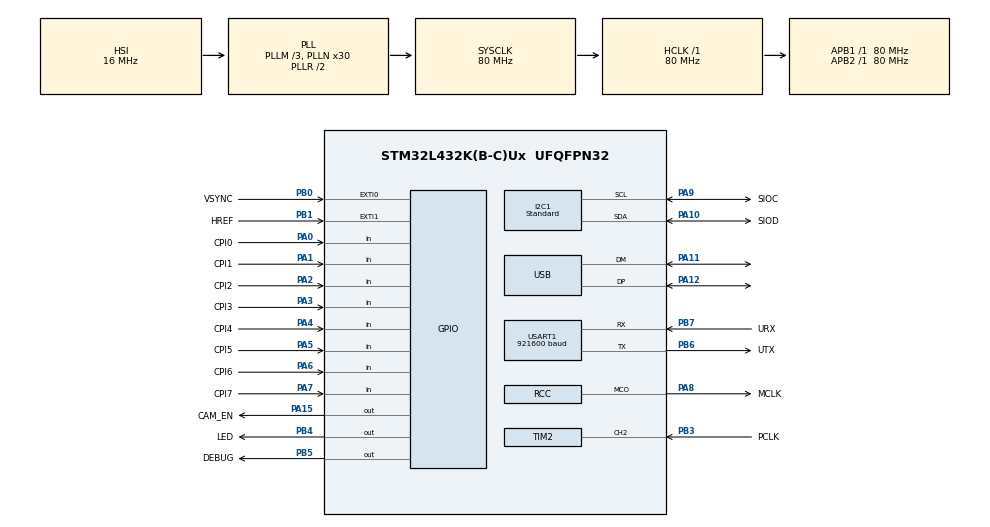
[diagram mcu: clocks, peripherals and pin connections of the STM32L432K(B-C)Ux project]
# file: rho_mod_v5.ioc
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Dma.Request0=TIM2_CH2/CH4
Dma.TIM2_CH2/CH4.0.Direction=DMA_PERIPH_TO_MEMORY
Dma.TIM2_CH2/CH4.0.Instance=DMA1_Channel7
Dma.TIM2_CH2/CH4.0.MemDataAlignment=DMA_MDATAALIGN_BYTE
Dma.TIM2_CH2/CH4.0.MemInc=DMA_MINC_ENABLE
Dma.TIM2_CH2/CH4.0.Mode=DMA_CIRCULAR
Dma.TIM2_CH2/CH4.0.PeriphDataAlignment=DMA_PDATAALIGN_BYTE
Dma.TIM2_CH2/CH4.0.PeriphInc=DMA_PINC_DISABLE
Dma.TIM2_CH2/CH4.0.Priority=DMA_PRIORITY_VERY_HIGH
I2C1.I2C_Speed_Mode=I2C_Standard
I2C1.OwnAddress=0x60
Mcu.Family=STM32L4
Mcu.Name=STM32L432K(B-C)Ux
Mcu.Package=UFQFPN32
NVIC.DMA1_Channel7_IRQn=true\:0\:0\:false\:true\:true\:4\:false\:true
NVIC.EXTI0_IRQn=true\:0\:2\:true\:true\:true\:1\:true\:true
NVIC.EXTI1_IRQn=true\:0\:1\:false\:true\:true\:2\:true\:true
NVIC.PriorityGroup=NVIC_PRIORITYGROUP_2
NVIC.USART1_IRQn=true\:0\:0\:false\:true\:true\:3\:true\:true
PA0.GPIO_Label=CPI0
PA0.Signal=GPIO_Input
PA1.GPIO_Label=CPI1
PA1.GPIO_Mode=GPIO_MODE_INPUT
PA1.GPIO_PuPd=GPIO_NOPULL
PA1.Signal=GPIO_Input
PA10.GPIO_Label=SIOD
PA10.Mode=I2C
PA10.Signal=I2C1_SDA
PA11.Mode=Device
PA11.Signal=USB_DM
PA12.Mode=Device
PA12.Signal=USB_DP
PA15\ (JTDI).GPIO_Label=CAM_EN
PA15\ (JTDI).GPIO_ModeDefaultOutputPP=GPIO_MODE_OUTPUT_PP
PA15\ (JTDI).GPIO_PuPd=GPIO_PULLUP
PA15\ (JTDI).GPIO_Speed=GPIO_SPEED_FREQ_LOW
PA15\ (JTDI).PinState=GPIO_PIN_RESET
PA15\ (JTDI).Signal=GPIO_Output
PA2.GPIO_Label=CPI2
PA2.GPIO_Mode=GPIO_MODE_INPUT
PA2.GPIO_PuPd=GPIO_NOPULL
PA2.Signal=GPIO_Input
PA3.GPIO_Label=CPI3
PA3.GPIO_Mode=GPIO_MODE_INPUT
PA3.GPIO_PuPd=GPIO_NOPULL
PA3.Signal=GPIO_Input
PA4.GPIO_Label=CPI4
PA4.GPIO_Mode=GPIO_MODE_INPUT
PA4.GPIO_PuPd=GPIO_NOPULL
PA4.Signal=GPIO_Input
PA5.GPIO_Label=CPI5
PA5.GPIO_Mode=GPIO_MODE_INPUT
PA5.GPIO_PuPd=GPIO_NOPULL
PA5.Signal=GPIO_Input
PA6.GPIO_Label=CPI6
PA6.GPIO_Mode=GPIO_MODE_INPUT
PA6.GPIO_PuPd=GPIO_NOPULL
PA6.Signal=GPIO_Input
PA7.GPIO_Label=CPI7
PA7.GPIO_Mode=GPIO_MODE_INPUT
PA7.GPIO_PuPd=GPIO_NOPULL
PA7.Signal=GPIO_Input
PA8.GPIO_Label=MCLK
PA8.Mode=Clock-out
PA8.Signal=RCC_MCO
PA9.GPIO_Label=SIOC
PA9.Mode=I2C
PA9.Signal=I2C1_SCL
PB0.GPIO_Label=VSYNC
PB0.GPIO_ModeDefaultEXTI=GPIO_MODE_IT_RISING_FALLING
PB0.GPIO_PuPd=GPIO_NOPULL
PB0.Signal=GPXTI0
PB1.GPIO_Label=HREF
PB1.GPIO_ModeDefaultEXTI=GPIO_MODE_IT_RISING_FALLING
PB1.Signal=GPXTI1
PB3\ (JTDO-TRACESWO).GPIO_Label=PCLK
PB3\ (JTDO-TRACESWO).GPIO_Speed=GPIO_SPEED_FREQ_VERY_HIGH
PB3\ (JTDO-TRACESWO).Signal=S_TIM2_CH2
PB4\ (NJTRST).GPIO_Label=LED
PB4\ (NJTRST).GPIO_PuPd=GPIO_PULLDOWN
PB4\ (NJTRST).Signal=GPIO_Output
PB5.GPIO_Label=DEBUG
PB5.Signal=GPIO_Output
PB6.GPIO_FM6=I2C_FASTMODEPLUS_PB6
PB6.GPIO_Label=UTX
PB6.Mode=Asynchronous
PB6.Signal=USART1_TX
PB7.GPIO_FM7=I2C_FASTMODEPLUS_PB7
PB7.GPIO_Label=URX
PB7.Mode=Asynchronous
PB7.Signal=USART1_RX
PC14-OSC32_IN\ (PC14).Mode=LSE-External-Oscillator
PC14-OSC32_IN\ (PC14).Signal=RCC_OSC32_IN
PC15-OSC32_OUT\ (PC15).Mode=LSE-External-Oscillator
PC15-OSC32_OUT\ (PC15).Signal=RCC_OSC32_OUT
ProjectManager.HeapSize=0x200
ProjectManager.StackSize=0x400
ProjectManager.TargetToolchain=EWARM V7
RCC.ADCFreq_Value=26666666.666666664
RCC.AHBFreq_Value=80000000
RCC.APB1Freq_Value=80000000
RCC.APB1TimFreq_Value=80000000
RCC.APB2Freq_Value=80000000
RCC.APB2TimFreq_Value=80000000
RCC.CK48CLockSelection=RCC_USBCLKSOURCE_HSI48
RCC.CortexFreq_Value=80000000
RCC.FLatency-AdvancedSettings=FLASH_LATENCY_4
RCC.HCLKFreq_Value=80000000
RCC.HSE_VALUE=48000000
RCC.HSI48_VALUE=48000000
RCC.HSI_VALUE=16000000
RCC.I2C1CLockSelection=RCC_I2C1CLKSOURCE_SYSCLK
RCC.MSIClockRange=RCC_MSIRANGE_11
RCC.MSI_VALUE=48000000
RCC.PLLM=3
RCC.PLLN=30
RCC.PLLSAI1N=10
RCC.PLLSourceVirtual=RCC_PLLSOURCE_HSI
RCC.RCC_MCO1Source=RCC_MCO1SOURCE_PLLCLK
RCC.RCC_MCODiv=RCC_MCODIV_4
RCC.SYSCLKFreq_VALUE=80000000
RCC.SYSCLKSource=RCC_SYSCLKSOURCE_PLLCLK
RCC.USBFreq_Value=48000000
RCC.VCOOutputFreq_Value=160000000
SH.S_TIM2_CH2.0=TIM2_CH2,Input_Capture2_from_TI2
SH.S_TIM2_CH2.1=TIM2_CH2,TriggerSource_TI2FP2
TIM2.AutoReloadPreload=TIM_AUTORELOAD_PRELOAD_ENABLE
TIM2.Channel-Input_Capture2_from_TI2=TIM_CHANNEL_2
TIM2.CounterMode=TIM_COUNTERMODE_UP
TIM2.ICFilter_CH2=0
TIM2.ICPolarity_CH2=TIM_INPUTCHANNELPOLARITY_FALLING
TIM2.Period=0
TIM2.TIM_MasterOutputTrigger=TIM_TRGO_OC1
USART1.BaudRate=921600
USART1.VirtualMode-Asynchronous=VM_ASYNC
VP_TIM2_VS_ControllerModeCombinedResetTrigger.Mode=Combined_Reset_Trigger_Mode
board=rho_mod_v4

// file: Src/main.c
/* USER CODE BEGIN Header */
/**
  ******************************************************************************
  * @file           : main.c
  * @brief          : Main program body
  ******************************************************************************
  * @attention
  *
  * <h2><center>&copy; Copyright (c) 2019 STMicroelectronics.
  * All rights reserved.</center></h2>
  *
  * This software component is licensed by ST under BSD 3-Clause license,
  * the "License"; You may not use this file except in compliance with the
  * License. You may obtain a copy of the License at:
  *                        opensource.org/licenses/BSD-3-Clause
  *
  ******************************************************************************
  */
/* USER CODE END Header */

#include "main.h"

/* USER CODE BEGIN Includes */
#include "master.h"
/* USER CODE END Includes */

I2C_HandleTypeDef hi2c1;

TIM_HandleTypeDef htim2;
DMA_HandleTypeDef hdma_tim2_ch2_ch4;

UART_HandleTypeDef huart1;

PCD_HandleTypeDef hpcd_USB_FS;

/* USER CODE BEGIN PV */
/* Private variables ---------------------------------------------------------*/

/* USER CODE END PV */

void SystemClock_Config(void);
static void MX_GPIO_Init(void);
static void MX_DMA_Init(void);
static void MX_I2C1_Init(void);
static void MX_USART1_UART_Init(void);
static void MX_TIM2_Init(void);
static void MX_USB_PCD_Init(void);
static void MX_NVIC_Init(void);
/* USER CODE BEGIN PFP */
/* Private function prototypes -----------------------------------------------*/

/* USER CODE END PFP */

int main(void)
{

  /* MCU Configuration--------------------------------------------------------*/

  /* Reset of all peripherals, Initializes the Flash interface and the Systick. */
  HAL_Init();

  /* Configure the system clock */
  SystemClock_Config();

  /* Initialize all configured peripherals */
  MX_GPIO_Init();
  MX_DMA_Init();
  MX_I2C1_Init();
  MX_USART1_UART_Init();
  MX_TIM2_Init();
  MX_USB_PCD_Init();

  /* Initialize interrupts */
  MX_NVIC_Init();
  /* USER CODE BEGIN 2 */
  MasterFunctions.Connect( &hi2c1, &htim2, &huart1 );
  /* USER CODE END 2 */

  /* Infinite loop */
  while (1)
  {

  }
}

void SystemClock_Config(void)
{
  RCC_OscInitTypeDef RCC_OscInitStruct = {0};
  RCC_ClkInitTypeDef RCC_ClkInitStruct = {0};
  RCC_PeriphCLKInitTypeDef PeriphClkInit = {0};

  /** Initializes the CPU, AHB and APB busses clocks
  */
  RCC_OscInitStruct.OscillatorType = RCC_OSCILLATORTYPE_HSI48|RCC_OSCILLATORTYPE_HSI;
  RCC_OscInitStruct.HSIState = RCC_HSI_ON;
  RCC_OscInitStruct.HSI48State = RCC_HSI48_ON;
  RCC_OscInitStruct.HSICalibrationValue = RCC_HSICALIBRATION_DEFAULT;
  RCC_OscInitStruct.PLL.PLLState = RCC_PLL_ON;
  RCC_OscInitStruct.PLL.PLLSource = RCC_PLLSOURCE_HSI;
  RCC_OscInitStruct.PLL.PLLM = 3;
  RCC_OscInitStruct.PLL.PLLN = 30;
  RCC_OscInitStruct.PLL.PLLP = RCC_PLLP_DIV7;
  RCC_OscInitStruct.PLL.PLLQ = RCC_PLLQ_DIV2;
  RCC_OscInitStruct.PLL.PLLR = RCC_PLLR_DIV2;
  if (HAL_RCC_OscConfig(&RCC_OscInitStruct) != HAL_OK)
  {
    Error_Handler();
  }
  /** Initializes the CPU, AHB and APB busses clocks
  */
  RCC_ClkInitStruct.ClockType = RCC_CLOCKTYPE_HCLK|RCC_CLOCKTYPE_SYSCLK
                              |RCC_CLOCKTYPE_PCLK1|RCC_CLOCKTYPE_PCLK2;
  RCC_ClkInitStruct.SYSCLKSource = RCC_SYSCLKSOURCE_PLLCLK;
  RCC_ClkInitStruct.AHBCLKDivider = RCC_SYSCLK_DIV1;
  RCC_ClkInitStruct.APB1CLKDivider = RCC_HCLK_DIV1;
  RCC_ClkInitStruct.APB2CLKDivider = RCC_HCLK_DIV1;

  if (HAL_RCC_ClockConfig(&RCC_ClkInitStruct, FLASH_LATENCY_4) != HAL_OK)
  {
    Error_Handler();
  }
  PeriphClkInit.PeriphClockSelection = RCC_PERIPHCLK_USART1|RCC_PERIPHCLK_I2C1
                              |RCC_PERIPHCLK_USB;
  PeriphClkInit.Usart1ClockSelection = RCC_USART1CLKSOURCE_PCLK2;
  PeriphClkInit.I2c1ClockSelection = RCC_I2C1CLKSOURCE_SYSCLK;
  PeriphClkInit.UsbClockSelection = RCC_USBCLKSOURCE_HSI48;
  if (HAL_RCCEx_PeriphCLKConfig(&PeriphClkInit) != HAL_OK)
  {
    Error_Handler();
  }
  HAL_RCC_MCOConfig(RCC_MCO1, RCC_MCO1SOURCE_PLLCLK, RCC_MCODIV_4);
  /** Configure the main internal regulator output voltage
  */
  if (HAL_PWREx_ControlVoltageScaling(PWR_REGULATOR_VOLTAGE_SCALE1) != HAL_OK)
  {
    Error_Handler();
  }
}

/**
  * @brief NVIC Configuration.
  * @retval None
  */
static void MX_NVIC_Init(void)
{
  /* EXTI0_IRQn interrupt configuration */
  HAL_NVIC_SetPriority(EXTI0_IRQn, 0, 2);
  HAL_NVIC_EnableIRQ(EXTI0_IRQn);
  /* EXTI1_IRQn interrupt configuration */
  HAL_NVIC_SetPriority(EXTI1_IRQn, 0, 1);
  HAL_NVIC_EnableIRQ(EXTI1_IRQn);
  /* USART1_IRQn interrupt configuration */
  HAL_NVIC_SetPriority(USART1_IRQn, 0, 0);
  HAL_NVIC_EnableIRQ(USART1_IRQn);
  /* DMA1_Channel7_IRQn interrupt configuration */
  HAL_NVIC_SetPriority(DMA1_Channel7_IRQn, 0, 0);
  HAL_NVIC_EnableIRQ(DMA1_Channel7_IRQn);
}

static void MX_I2C1_Init(void)
{

  hi2c1.Instance = I2C1;
  hi2c1.Init.Timing = 0x10909CEC;
  hi2c1.Init.OwnAddress1 = 192;
  hi2c1.Init.AddressingMode = I2C_ADDRESSINGMODE_7BIT;
  hi2c1.Init.DualAddressMode = I2C_DUALADDRESS_DISABLE;
  hi2c1.Init.OwnAddress2 = 0;
  hi2c1.Init.OwnAddress2Masks = I2C_OA2_NOMASK;
  hi2c1.Init.GeneralCallMode = I2C_GENERALCALL_DISABLE;
  hi2c1.Init.NoStretchMode = I2C_NOSTRETCH_DISABLE;
  if (HAL_I2C_Init(&hi2c1) != HAL_OK)
  {
    Error_Handler();
  }
  /** Configure Analogue filter
  */
  if (HAL_I2CEx_ConfigAnalogFilter(&hi2c1, I2C_ANALOGFILTER_ENABLE) != HAL_OK)
  {
    Error_Handler();
  }
  /** Configure Digital filter
  */
  if (HAL_I2CEx_ConfigDigitalFilter(&hi2c1, 0) != HAL_OK)
  {
    Error_Handler();
  }

}

static void MX_TIM2_Init(void)
{

  TIM_SlaveConfigTypeDef sSlaveConfig = {0};
  TIM_MasterConfigTypeDef sMasterConfig = {0};
  TIM_IC_InitTypeDef sConfigIC = {0};

  htim2.Instance = TIM2;
  htim2.Init.Prescaler = 0;
  htim2.Init.CounterMode = TIM_COUNTERMODE_UP;
  htim2.Init.Period = 0;
  htim2.Init.ClockDivision = TIM_CLOCKDIVISION_DIV1;
  htim2.Init.AutoReloadPreload = TIM_AUTORELOAD_PRELOAD_ENABLE;
  if (HAL_TIM_Base_Init(&htim2) != HAL_OK)
  {
    Error_Handler();
  }
  if (HAL_TIM_IC_Init(&htim2) != HAL_OK)
  {
    Error_Handler();
  }
  sSlaveConfig.SlaveMode = TIM_SLAVEMODE_COMBINED_RESETTRIGGER;
  sSlaveConfig.InputTrigger = TIM_TS_TI2FP2;
  sSlaveConfig.TriggerPolarity = TIM_INPUTCHANNELPOLARITY_FALLING;
  sSlaveConfig.TriggerFilter = 0;
  if (HAL_TIM_SlaveConfigSynchronization(&htim2, &sSlaveConfig) != HAL_OK)
  {
    Error_Handler();
  }
  sMasterConfig.MasterOutputTrigger = TIM_TRGO_OC1;
  sMasterConfig.MasterSlaveMode = TIM_MASTERSLAVEMODE_DISABLE;
  if (HAL_TIMEx_MasterConfigSynchronization(&htim2, &sMasterConfig) != HAL_OK)
  {
    Error_Handler();
  }
  sConfigIC.ICPolarity = TIM_INPUTCHANNELPOLARITY_FALLING;
  sConfigIC.ICSelection = TIM_ICSELECTION_DIRECTTI;
  sConfigIC.ICPrescaler = TIM_ICPSC_DIV1;
  sConfigIC.ICFilter = 0;
  if (HAL_TIM_IC_ConfigChannel(&htim2, &sConfigIC, TIM_CHANNEL_2) != HAL_OK)
  {
    Error_Handler();
  }

}

static void MX_USART1_UART_Init(void)
{

  huart1.Instance = USART1;
  huart1.Init.BaudRate = 921600;
  huart1.Init.WordLength = UART_WORDLENGTH_8B;
  huart1.Init.StopBits = UART_STOPBITS_1;
  huart1.Init.Parity = UART_PARITY_NONE;
  huart1.Init.Mode = UART_MODE_TX_RX;
  huart1.Init.HwFlowCtl = UART_HWCONTROL_NONE;
  huart1.Init.OverSampling = UART_OVERSAMPLING_16;
  huart1.Init.OneBitSampling = UART_ONE_BIT_SAMPLE_DISABLE;
  huart1.AdvancedInit.AdvFeatureInit = UART_ADVFEATURE_NO_INIT;
  if (HAL_UART_Init(&huart1) != HAL_OK)
  {
    Error_Handler();
  }

}

static void MX_USB_PCD_Init(void)
{

  hpcd_USB_FS.Instance = USB;
  hpcd_USB_FS.Init.dev_endpoints = 8;
  hpcd_USB_FS.Init.speed = PCD_SPEED_FULL;
  hpcd_USB_FS.Init.phy_itface = PCD_PHY_EMBEDDED;
  hpcd_USB_FS.Init.Sof_enable = DISABLE;
  hpcd_USB_FS.Init.low_power_enable = DISABLE;
  hpcd_USB_FS.Init.lpm_enable = DISABLE;
  hpcd_USB_FS.Init.battery_charging_enable = DISABLE;
  if (HAL_PCD_Init(&hpcd_USB_FS) != HAL_OK)
  {
    Error_Handler();
  }

}

static void MX_DMA_Init(void)
{
  /* DMA controller clock enable */
  __HAL_RCC_DMA1_CLK_ENABLE();

}

static void MX_GPIO_Init(void)
{
  GPIO_InitTypeDef GPIO_InitStruct = {0};

  /* GPIO Ports Clock Enable */
  __HAL_RCC_GPIOC_CLK_ENABLE();
  __HAL_RCC_GPIOA_CLK_ENABLE();
  __HAL_RCC_GPIOB_CLK_ENABLE();

  /*Configure GPIO pin Output Level */
  HAL_GPIO_WritePin(CAM_EN_GPIO_Port, CAM_EN_Pin, GPIO_PIN_RESET);

  /*Configure GPIO pin Output Level */
  HAL_GPIO_WritePin(GPIOB, LED_Pin|DEBUG_Pin, GPIO_PIN_RESET);

  /*Configure GPIO pins : CPI0_Pin CPI1_Pin CPI2_Pin CPI3_Pin
                           CPI4_Pin CPI5_Pin CPI6_Pin CPI7_Pin */
  GPIO_InitStruct.Pin = CPI0_Pin|CPI1_Pin|CPI2_Pin|CPI3_Pin
                          |CPI4_Pin|CPI5_Pin|CPI6_Pin|CPI7_Pin;
  GPIO_InitStruct.Mode = GPIO_MODE_INPUT;
  GPIO_InitStruct.Pull = GPIO_NOPULL;
  HAL_GPIO_Init(GPIOA, &GPIO_InitStruct);

  /*Configure GPIO pins : VSYNC_Pin HREF_Pin */
  GPIO_InitStruct.Pin = VSYNC_Pin|HREF_Pin;
  GPIO_InitStruct.Mode = GPIO_MODE_IT_RISING_FALLING;
  GPIO_InitStruct.Pull = GPIO_NOPULL;
  HAL_GPIO_Init(GPIOB, &GPIO_InitStruct);

  /*Configure GPIO pin : MCLK_Pin */
  GPIO_InitStruct.Pin = MCLK_Pin;
  GPIO_InitStruct.Mode = GPIO_MODE_AF_PP;
  GPIO_InitStruct.Pull = GPIO_NOPULL;
  GPIO_InitStruct.Speed = GPIO_SPEED_FREQ_LOW;
  GPIO_InitStruct.Alternate = GPIO_AF0_MCO;
  HAL_GPIO_Init(MCLK_GPIO_Port, &GPIO_InitStruct);

  /*Configure GPIO pin : CAM_EN_Pin */
  GPIO_InitStruct.Pin = CAM_EN_Pin;
  GPIO_InitStruct.Mode = GPIO_MODE_OUTPUT_PP;
  GPIO_InitStruct.Pull = GPIO_PULLUP;
  GPIO_InitStruct.Speed = GPIO_SPEED_FREQ_LOW;
  HAL_GPIO_Init(CAM_EN_GPIO_Port, &GPIO_InitStruct);

  /*Configure GPIO pin : LED_Pin */
  GPIO_InitStruct.Pin = LED_Pin;
  GPIO_InitStruct.Mode = GPIO_MODE_OUTPUT_PP;
  GPIO_InitStruct.Pull = GPIO_PULLDOWN;
  GPIO_InitStruct.Speed = GPIO_SPEED_FREQ_LOW;
  HAL_GPIO_Init(LED_GPIO_Port, &GPIO_InitStruct);

  /*Configure GPIO pin : DEBUG_Pin */
  GPIO_InitStruct.Pin = DEBUG_Pin;
  GPIO_InitStruct.Mode = GPIO_MODE_OUTPUT_PP;
  GPIO_InitStruct.Pull = GPIO_NOPULL;
  GPIO_InitStruct.Speed = GPIO_SPEED_FREQ_LOW;
  HAL_GPIO_Init(DEBUG_GPIO_Port, &GPIO_InitStruct);

}

void Error_Handler(void)
{
  while(1)
  {
  }
}

/************************ (C) COPYRIGHT STMicroelectronics *****END OF FILE****/
